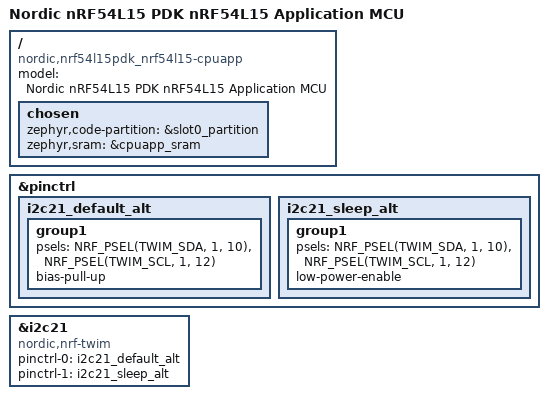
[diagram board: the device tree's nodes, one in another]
/*
 * Copyright (c) 2024 Nordic Semiconductor ASA
 *
 * SPDX-License-Identifier: Apache-2.0
 */

/dts-v1/;

#include "nrf54l15_cpuapp_common.dtsi"

/ {
	compatible = "nordic,nrf54l15pdk_nrf54l15-cpuapp";
	model = "Nordic nRF54L15 PDK nRF54L15 Application MCU";

	chosen {
		zephyr,code-partition = &slot0_partition;
		zephyr,sram = &cpuapp_sram;
	};
};

&pinctrl {
	i2c21_default_alt: i2c21_default_alt {
		group1 {
			psels = <NRF_PSEL(TWIM_SDA, 1, 10)>,
				<NRF_PSEL(TWIM_SCL, 1, 12)>;
			bias-pull-up;
		};
	};
	i2c21_sleep_alt: i2c21_sleep_alt {
		group1 {
			psels = <NRF_PSEL(TWIM_SDA, 1, 10)>,
				<NRF_PSEL(TWIM_SCL, 1, 12)>;
			low-power-enable;
		};
	};
};
arduino_i2c: &i2c21 {
	compatible = "nordic,nrf-twim";
	status = "okay";
	pinctrl-0 = <&i2c21_default_alt>;
	pinctrl-1 = <&i2c21_sleep_alt>;
	pinctrl-names = "default", "sleep";
};
